# JTAG register map
Vendor: litex
Registers are 32-bit, read-write, reset 0x0 unless marked. A register's access mark holds for its fields unless they carry their own. Offsets are from the block's base; [hi:lo] are bit positions; {n}, {i} and the like mark numbered series; 'fields as' and 'values as' point back to an identical list.

## SEED
Base 0xF0014000
0x00 SEED1 ro reset 0x16FE161D — Bits 32-63 of `SEED_SEED`. Seed used for the build
  [31:0] seed
0x04 SEED0 ro reset 0x22DC1638 — Bits 0-31 of `SEED_SEED`.
  [31:0] seed

## ROMTEST
Base 0xF0015000
0x00 ADDRESS — address for ROM
  [7:0] address
0x04 DATA ro — data from ROM

## AUDIO
Base 0xF0016000
0x00 EV_STATUS
  [3:0] status
0x04 EV_PENDING
  [3:0] pending
0x08 EV_ENABLE
  [3:0] enable
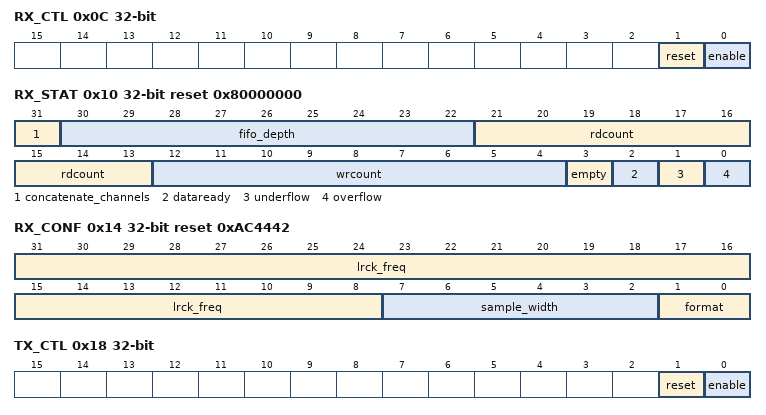
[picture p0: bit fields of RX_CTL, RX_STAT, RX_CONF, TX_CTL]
0x0C RX_CTL — Rx data path control
  [1] reset — Writing `1` resets the FIFO. Reset happens regardless of enable state.
  [0] enable — Enable the receiving data
0x10 RX_STAT ro reset 0x80000000 — Rx data path status
  [31] concatenate_channels — Receive and send both channels atomically
  [30:22] fifo_depth — FIFO depth as synthesized
  [21:13] rdcount — Read count
  [12:4] wrcount — Write count
  [3] empty — No data available in FIFO to read
  [2] dataready — 256 words of data loaded and ready to read
  [1] underflow — Rx underflow
  [0] overflow — Rx overflow
0x14 RX_CONF ro reset 0xAC4442 — Rx configuration
  [31:8] lrck_freq — Audio sampling rate frequency
  [7:2] sample_width — Single sample width
  [1:0] format — I2S sample format. I2S_FORMAT.I2S_LEFT_JUSTIFIED is left-justified, I2S_FORMAT.I2S_STANDARD is I2S standard
0x18 TX_CTL — Tx data path control
  [1] reset — Writing `1` resets the FIFO. Reset happens regardless of enable state.
  [0] enable — Enable the transmission data
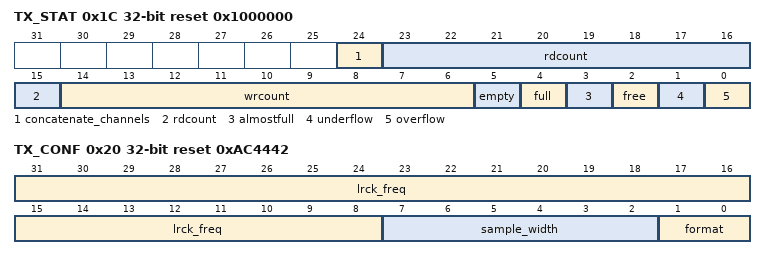
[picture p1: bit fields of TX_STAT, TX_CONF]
0x1C TX_STAT ro reset 0x1000000 — Tx data path status
  [24] concatenate_channels — Receive and send both channels atomically
  [23:15] rdcount — Tx read count
  [14:6] wrcount — Tx write count
  [5] empty — FIFO is empty
  [4] full — FIFO is full or overfull
  [3] almostfull — Less than 8 words space available
  [2] free — At least 256 words of space free
  [1] underflow — Tx underflow
  [0] overflow — Tx overflow
0x20 TX_CONF ro reset 0xAC4442 — TX configuration
  fields as RX_CONF

## TRNG_OSC
Base 0xF0017000
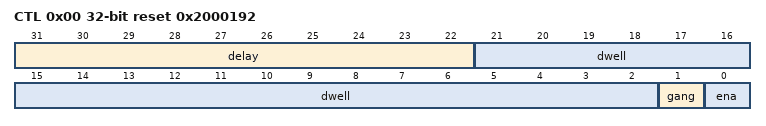
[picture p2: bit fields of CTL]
0x00 CTL reset 0x2000192
  [31:22] delay — Sampler delay time. Sets the delay between when the small rings are merged together, and when the final entropy result is sampled. Value encodes number of sysclk edges to pass during the delay period. Delay should be long enough for the signal to propagate around the merged ring, but longer times also means more coupling of the deterministic sysclk noise into the rings.
  [21:2] dwell — Prescaler to set dwell-time of entropy collection. Controls the period of how long the oscillators are in a metastable state to collect entropy before sampling. Value encodes the number of sysclk edges to pass during the dwell period.
  [1] gang — Fold in collective gang entropy during dwell time
  [0] ena — Enable the TRNG; 0 puts the TRNG into full powerdown
0x04 RAND ro reset 0xDEADBEEF
  [31:0] rand — Random data shifted into a register for easier collection.
0x08 STATUS ro
  [0] fresh — When set, the rand register contains a fresh set of bits to be read; cleaned by reading the `rand` register

## AES
Base 0xF0018000
0x00 KEY_0_Q
  [31:0] key_0 — least significant key word
{0x0+4i} KEY_{i}_Q (i=1..6)
  [31:0] key_{i} — key word {i}
0x1C KEY_7_Q
  [31:0] key_7 — most significant key word
{0x20+4i} DATAOUT_{i} ro (i=0..3)
  [31:0] data_{i} — data output from cipher
{0x30+4i} DATAIN_{i} (i=0..3)
  [31:0] data_{i} — data input
{0x40+4i} IV_{i} (i=0..3)
  [31:0] iv_{i} — iv
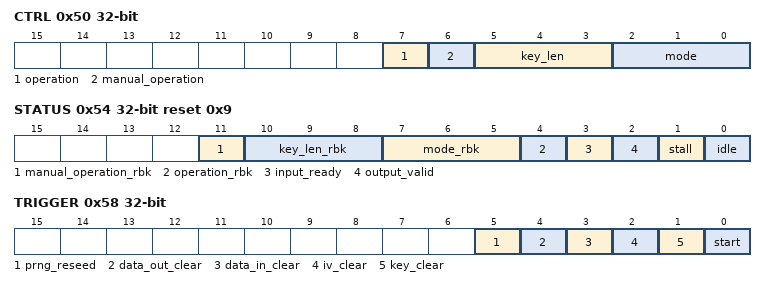
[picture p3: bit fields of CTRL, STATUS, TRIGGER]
0x50 CTRL
  [7] operation — Sets encrypt/decrypt operation. `0` = encrypt, `1` = decrypt
  [6] manual_operation — If `1`, operation starts when `trigger` bit `start` is written, otherwise automatically on data and IV ready
  [5:3] key_len — length of the aes block. Illegal values mapped to `AES128`
  [2:0] mode — set cipher mode. Illegal values mapped to `AES_ECB`
0x54 STATUS ro reset 0x9
  [11] manual_operation_rbk — Manual operation readback
  [10:8] key_len_rbk — Actual key length selected by the hardware readback
  [7:5] mode_rbk — Actual mode selected by hardware readback
  [4] operation_rbk — Operation readback
  [3] input_ready — Input value has been latched and it is OK to update to a new value
  [2] output_valid — Data output valid
  [1] stall — Core stall
  [0] idle — Core idle
0x58 TRIGGER
  [5] prng_reseed — Reseed PRNG
  [4] data_out_clear — Clears the data output
  [3] data_in_clear — Clears data input
  [2] iv_clear — Clears the IV
  [1] key_clear — Clears the key
  [0] start — Triggers an AES computation if manual_start is selected
